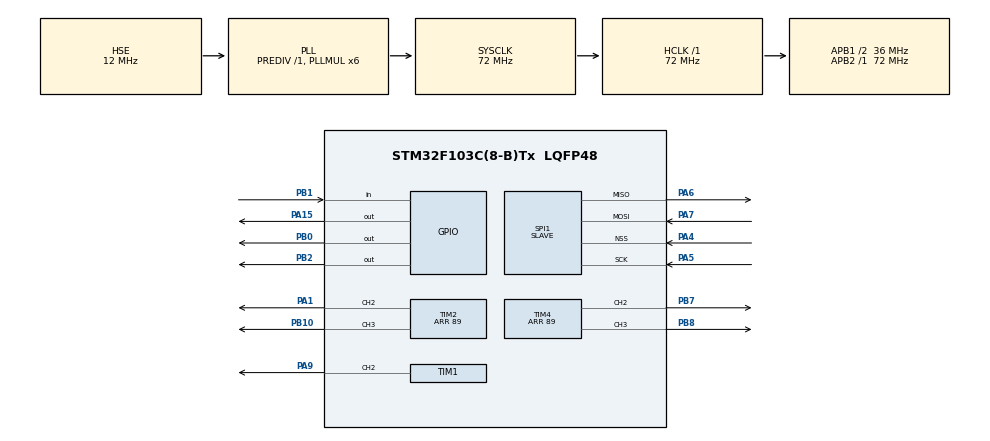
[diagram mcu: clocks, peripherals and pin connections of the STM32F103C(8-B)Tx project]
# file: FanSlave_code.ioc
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Dma.Request0=TIM2_CH2/CH4
Dma.Request1=TIM2_CH3
Dma.Request2=TIM1_CH2
Dma.Request3=TIM4_CH2
Dma.Request4=TIM4_CH3
Dma.TIM1_CH2.2.Direction=DMA_MEMORY_TO_PERIPH
Dma.TIM1_CH2.2.Instance=DMA1_Channel3
Dma.TIM1_CH2.2.MemDataAlignment=DMA_MDATAALIGN_BYTE
Dma.TIM1_CH2.2.MemInc=DMA_MINC_ENABLE
Dma.TIM1_CH2.2.Mode=DMA_NORMAL
Dma.TIM1_CH2.2.PeriphDataAlignment=DMA_PDATAALIGN_HALFWORD
Dma.TIM1_CH2.2.PeriphInc=DMA_PINC_DISABLE
Dma.TIM1_CH2.2.Priority=DMA_PRIORITY_LOW
Dma.TIM2_CH2/CH4.0.Direction=DMA_PERIPH_TO_MEMORY
Dma.TIM2_CH2/CH4.0.Instance=DMA1_Channel7
Dma.TIM2_CH2/CH4.0.MemDataAlignment=DMA_MDATAALIGN_BYTE
Dma.TIM2_CH2/CH4.0.MemInc=DMA_MINC_ENABLE
Dma.TIM2_CH2/CH4.0.Mode=DMA_CIRCULAR
Dma.TIM2_CH2/CH4.0.PeriphDataAlignment=DMA_PDATAALIGN_HALFWORD
Dma.TIM2_CH2/CH4.0.PeriphInc=DMA_PINC_DISABLE
Dma.TIM2_CH2/CH4.0.Priority=DMA_PRIORITY_LOW
Dma.TIM2_CH3.1.Direction=DMA_MEMORY_TO_PERIPH
Dma.TIM2_CH3.1.Instance=DMA1_Channel1
Dma.TIM2_CH3.1.MemDataAlignment=DMA_MDATAALIGN_BYTE
Dma.TIM2_CH3.1.MemInc=DMA_MINC_ENABLE
Dma.TIM2_CH3.1.Mode=DMA_NORMAL
Dma.TIM2_CH3.1.PeriphDataAlignment=DMA_PDATAALIGN_HALFWORD
Dma.TIM2_CH3.1.PeriphInc=DMA_PINC_DISABLE
Dma.TIM2_CH3.1.Priority=DMA_PRIORITY_LOW
Dma.TIM4_CH2.3.Direction=DMA_MEMORY_TO_PERIPH
Dma.TIM4_CH2.3.Instance=DMA1_Channel4
Dma.TIM4_CH2.3.MemDataAlignment=DMA_MDATAALIGN_BYTE
Dma.TIM4_CH2.3.MemInc=DMA_MINC_ENABLE
Dma.TIM4_CH2.3.Mode=DMA_NORMAL
Dma.TIM4_CH2.3.PeriphDataAlignment=DMA_PDATAALIGN_HALFWORD
Dma.TIM4_CH2.3.PeriphInc=DMA_PINC_DISABLE
Dma.TIM4_CH2.3.Priority=DMA_PRIORITY_LOW
Dma.TIM4_CH3.4.Direction=DMA_MEMORY_TO_PERIPH
Dma.TIM4_CH3.4.Instance=DMA1_Channel5
Dma.TIM4_CH3.4.MemDataAlignment=DMA_MDATAALIGN_BYTE
Dma.TIM4_CH3.4.MemInc=DMA_MINC_ENABLE
Dma.TIM4_CH3.4.Mode=DMA_NORMAL
Dma.TIM4_CH3.4.PeriphDataAlignment=DMA_PDATAALIGN_HALFWORD
Dma.TIM4_CH3.4.PeriphInc=DMA_PINC_DISABLE
Dma.TIM4_CH3.4.Priority=DMA_PRIORITY_LOW
Mcu.Family=STM32F1
Mcu.Name=STM32F103C(8-B)Tx
Mcu.Package=LQFP48
NVIC.DMA1_Channel1_IRQn=true\:0\:0\:false\:false\:true\:false\:true\:true
NVIC.DMA1_Channel3_IRQn=true\:0\:0\:false\:false\:true\:false\:true\:true
NVIC.DMA1_Channel4_IRQn=true\:0\:0\:false\:false\:true\:false\:true\:true
NVIC.DMA1_Channel5_IRQn=true\:0\:0\:false\:false\:true\:false\:true\:true
NVIC.DMA1_Channel7_IRQn=true\:0\:0\:false\:false\:true\:false\:true\:true
NVIC.PriorityGroup=NVIC_PRIORITYGROUP_4
NVIC.SPI1_IRQn=true\:0\:0\:false\:false\:true\:true\:true\:true
NVIC.TIM3_IRQn=true\:0\:0\:false\:false\:true\:true\:true\:true
NVIC.TIM4_IRQn=true\:0\:0\:false\:false\:true\:true\:true\:true
PA1.Signal=S_TIM2_CH2
PA13.Mode=Serial_Wire
PA13.Signal=SYS_JTMS-SWDIO
PA14.Mode=Serial_Wire
PA14.Signal=SYS_JTCK-SWCLK
PA15.Signal=GPIO_Output
PA4.Mode=NSS_Signal_Hard_Input
PA4.Signal=SPI1_NSS
PA5.Mode=Full_Duplex_Slave
PA5.Signal=SPI1_SCK
PA6.Mode=Full_Duplex_Slave
PA6.Signal=SPI1_MISO
PA7.Mode=Full_Duplex_Slave
PA7.Signal=SPI1_MOSI
PA9.Signal=S_TIM1_CH2
PB0.Signal=GPIO_Output
PB1.Signal=GPIO_Input
PB10.Signal=S_TIM2_CH3
PB2.Signal=GPIO_Output
PB7.Signal=S_TIM4_CH2
PB8.Signal=S_TIM4_CH3
PB9.Signal=S_TIM4_CH4
PD0-OSC_IN.Mode=HSE-External-Oscillator
PD0-OSC_IN.Signal=RCC_OSC_IN
PD1-OSC_OUT.Mode=HSE-External-Oscillator
PD1-OSC_OUT.Signal=RCC_OSC_OUT
ProjectManager.HeapSize=0x200
ProjectManager.StackSize=0x400
ProjectManager.TargetToolchain=STM32CubeIDE
RCC.AHBFreq_Value=72000000
RCC.APB1CLKDivider=RCC_HCLK_DIV2
RCC.APB1Freq_Value=36000000
RCC.APB1TimFreq_Value=72000000
RCC.APB2Freq_Value=72000000
RCC.APB2TimFreq_Value=72000000
RCC.HCLKFreq_Value=72000000
RCC.HSE_VALUE=12000000
RCC.PLLMUL=RCC_PLL_MUL6
RCC.PLLSourceVirtual=RCC_PLLSOURCE_HSE
RCC.SYSCLKFreq_VALUE=72000000
RCC.SYSCLKSource=RCC_SYSCLKSOURCE_PLLCLK
RCC.USBFreq_Value=72000000
SH.S_TIM1_CH2.0=TIM1_CH2,PWM Generation2 CH2
SH.S_TIM2_CH2.0=TIM2_CH2,PWM Generation2 CH2
SH.S_TIM2_CH3.0=TIM2_CH3,PWM Generation3 CH3
SH.S_TIM4_CH2.0=TIM4_CH2,PWM Generation2 CH2
SH.S_TIM4_CH3.0=TIM4_CH3,PWM Generation3 CH3
SH.S_TIM4_CH4.0=TIM4_CH4
SPI1.Direction=SPI_DIRECTION_2LINES
SPI1.FirstBit=SPI_FIRSTBIT_LSB
SPI1.Mode=SPI_MODE_SLAVE
SPI1.VirtualNSS=VM_NSSHARD
SPI1.VirtualType=VM_SLAVE
TIM1.Channel-PWM\ Generation2\ CH2=TIM_CHANNEL_2
TIM1.Period=89
TIM2.Channel-PWM\ Generation2\ CH2=TIM_CHANNEL_2
TIM2.Channel-PWM\ Generation3\ CH3=TIM_CHANNEL_3
TIM2.Period=89
TIM3.Period=999
TIM3.Prescaler=71
TIM4.Channel-PWM\ Generation2\ CH2=TIM_CHANNEL_2
TIM4.Channel-PWM\ Generation3\ CH3=TIM_CHANNEL_3
TIM4.Period=89
VP_TIM3_VS_ClockSourceINT.Mode=Internal
board=custom

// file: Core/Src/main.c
/* USER CODE BEGIN Header */
/**
  ******************************************************************************
  * @file           : main.c
  * @brief          : Main program body
  ******************************************************************************
  * @attention
  *
  * Copyright (c) 2023 STMicroelectronics.
  * All rights reserved.
  *
  * This software is licensed under terms that can be found in the LICENSE file
  * in the root directory of this software component.
  * If no LICENSE file comes with this software, it is provided AS-IS.
  *
  ******************************************************************************
  */
/* USER CODE END Header */
#include "main.h"
#include "dma.h"
#include "spi.h"
#include "tim.h"
#include "gpio.h"

/* USER CODE BEGIN Includes */
#include "ws2812.h"
#include "HX711.h"
#include "fsm.h"
#include <string.h>
#include <stdlib.h>
/* USER CODE END Includes */

void SystemClock_Config(void);

/* USER CODE BEGIN 0 */
unsigned int init_kg;

/* USER CODE END 0 */

int main(void) {

    /* MCU Configuration--------------------------------------------------------*/

    /* Reset of all peripherals, Initializes the Flash interface and the Systick. */
    HAL_Init();

    /* Configure the system clock */
    SystemClock_Config();

    /* Initialize all configured peripherals */
    MX_GPIO_Init();
    MX_DMA_Init();
    MX_SPI1_Init();
    MX_TIM4_Init();
    MX_TIM2_Init();
    MX_TIM3_Init();
    MX_TIM1_Init();
    /* USER CODE BEGIN 2 */
    WS2812_Init();
    HAL_TIM_Base_Start_IT(&htim3);
    HAL_GPIO_WritePin(GPIOB, GPIO_PIN_2, GPIO_PIN_SET);
    /* USER CODE END 2 */
    //HAL_GPIO_WritePin(GPIOA, GPIO_PIN_15, GPIO_PIN_SET);

    /* Infinite loop */
    /* USER CODE BEGIN WHILE */
    // init_kg = HX711_ReadCount();
    int i = 0;
    while (1) {
        /* USER CODE END WHILE */

        /* USER CODE BEGIN 3 */

        WS2812_Load();
        //HAL_Delay(200);
    }
    /* USER CODE END 3 */
}

void SystemClock_Config(void) {
    RCC_OscInitTypeDef RCC_OscInitStruct = {0};
    RCC_ClkInitTypeDef RCC_ClkInitStruct = {0};

    /** Initializes the RCC Oscillators according to the specified parameters
    * in the RCC_OscInitTypeDef structure.
    */
    RCC_OscInitStruct.OscillatorType = RCC_OSCILLATORTYPE_HSE;
    RCC_OscInitStruct.HSEState = RCC_HSE_ON;
    RCC_OscInitStruct.HSEPredivValue = RCC_HSE_PREDIV_DIV1;
    RCC_OscInitStruct.HSIState = RCC_HSI_ON;
    RCC_OscInitStruct.PLL.PLLState = RCC_PLL_ON;
    RCC_OscInitStruct.PLL.PLLSource = RCC_PLLSOURCE_HSE;
    RCC_OscInitStruct.PLL.PLLMUL = RCC_PLL_MUL6;
    if (HAL_RCC_OscConfig(&RCC_OscInitStruct) != HAL_OK) {
        Error_Handler();
    }

    /** Initializes the CPU, AHB and APB buses clocks
    */
    RCC_ClkInitStruct.ClockType = RCC_CLOCKTYPE_HCLK | RCC_CLOCKTYPE_SYSCLK
                                  | RCC_CLOCKTYPE_PCLK1 | RCC_CLOCKTYPE_PCLK2;
    RCC_ClkInitStruct.SYSCLKSource = RCC_SYSCLKSOURCE_PLLCLK;
    RCC_ClkInitStruct.AHBCLKDivider = RCC_SYSCLK_DIV1;
    RCC_ClkInitStruct.APB1CLKDivider = RCC_HCLK_DIV2;
    RCC_ClkInitStruct.APB2CLKDivider = RCC_HCLK_DIV1;

    if (HAL_RCC_ClockConfig(&RCC_ClkInitStruct, FLASH_LATENCY_2) != HAL_OK) {
        Error_Handler();
    }
}

void Error_Handler(void) {
    __disable_irq();
    while (1) {
    }
}
